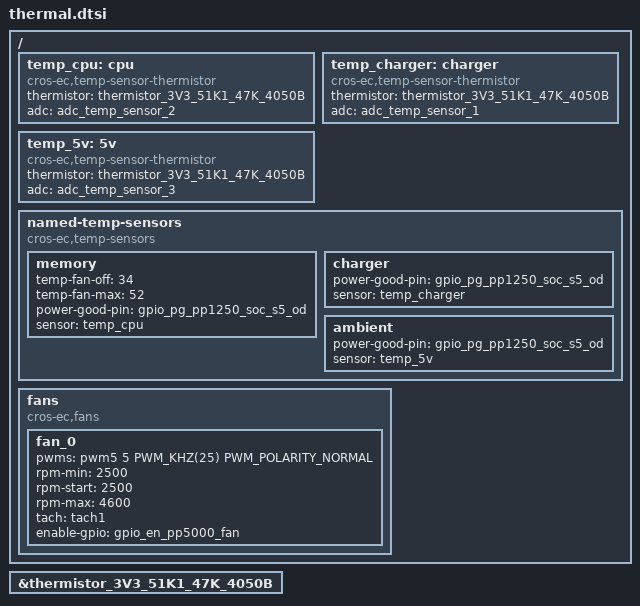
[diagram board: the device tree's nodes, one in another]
/* Copyright 2025 The ChromiumOS Authors
 * Use of this source code is governed by a BSD-style license that can be
 * found in the LICENSE file.
 */
#include <cros/thermistor/thermistor.dtsi>

 / {
	temp_cpu: cpu {
		compatible = "cros-ec,temp-sensor-thermistor";
		thermistor = <&thermistor_3V3_51K1_47K_4050B>;
		adc = <&adc_temp_sensor_2>;
	};
	temp_charger: charger {
		compatible = "cros-ec,temp-sensor-thermistor";
		thermistor = <&thermistor_3V3_51K1_47K_4050B>;
		adc = <&adc_temp_sensor_1>;
	};
	temp_5v: 5v {
		compatible = "cros-ec,temp-sensor-thermistor";
		thermistor = <&thermistor_3V3_51K1_47K_4050B>;
		adc = <&adc_temp_sensor_3>;
	};

	named-temp-sensors {
		compatible = "cros-ec,temp-sensors";
		memory {
			temp-fan-off = <34>;
			temp-fan-max = <52>;
			power-good-pin = <&gpio_pg_pp1250_soc_s5_od>;
			sensor = <&temp_cpu>;
		};
		charger {
			power-good-pin = <&gpio_pg_pp1250_soc_s5_od>;
			sensor = <&temp_charger>;
		};
		ambient {
			power-good-pin = <&gpio_pg_pp1250_soc_s5_od>;
			sensor = <&temp_5v>;
		};
	};

	fans {
		compatible = "cros-ec,fans";

		fan_0 {
			pwms = <&pwm5 5 PWM_KHZ(25) PWM_POLARITY_NORMAL>;
			rpm-min = <2500>;
			rpm-start = <2500>;
			rpm-max = <4600>;
			tach = <&tach1>;
			enable-gpio = <&gpio_en_pp5000_fan>;
		};
	};
 };

&thermistor_3V3_51K1_47K_4050B {
	status = "okay";
};
